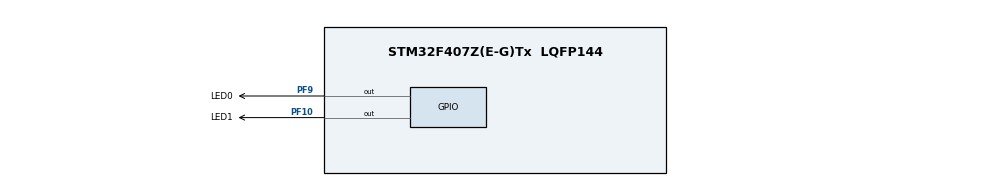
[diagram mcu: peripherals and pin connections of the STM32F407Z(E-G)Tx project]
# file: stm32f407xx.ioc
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Mcu.Family=STM32F4
Mcu.Name=STM32F407Z(E-G)Tx
Mcu.Package=LQFP144
NVIC.PriorityGroup=NVIC_PRIORITYGROUP_4
PA13.Mode=Serial_Wire
PA13.Signal=SYS_JTMS-SWDIO
PA14.Mode=Serial_Wire
PA14.Signal=SYS_JTCK-SWCLK
PC14-OSC32_IN.Mode=LSE-External-Oscillator
PC14-OSC32_IN.Signal=RCC_OSC32_IN
PC15-OSC32_OUT.Mode=LSE-External-Oscillator
PC15-OSC32_OUT.Signal=RCC_OSC32_OUT
PF10.GPIO_Label=LED1
PF10.GPIO_PuPd=GPIO_PULLUP
PF10.GPIO_Speed=GPIO_SPEED_FREQ_HIGH
PF10.PinState=GPIO_PIN_SET
PF10.Signal=GPIO_Output
PF9.GPIO_Label=LED0
PF9.GPIO_PuPd=GPIO_PULLUP
PF9.GPIO_Speed=GPIO_SPEED_FREQ_HIGH
PF9.PinState=GPIO_PIN_SET
PF9.Signal=GPIO_Output
PH0-OSC_IN.Mode=HSE-External-Oscillator
PH0-OSC_IN.Signal=RCC_OSC_IN
PH1-OSC_OUT.Mode=HSE-External-Oscillator
PH1-OSC_OUT.Signal=RCC_OSC_OUT
ProjectManager.HeapSize=0x200
ProjectManager.StackSize=0x400
ProjectManager.TargetToolchain=Makefile
RCC.48MHZClocksFreq_Value=84000000
RCC.AHBFreq_Value=168000000
RCC.APB1CLKDivider=RCC_HCLK_DIV4
RCC.APB1Freq_Value=42000000
RCC.APB1TimFreq_Value=84000000
RCC.APB2CLKDivider=RCC_HCLK_DIV2
RCC.APB2Freq_Value=84000000
RCC.APB2TimFreq_Value=168000000
RCC.CortexFreq_Value=168000000
RCC.HCLKFreq_Value=168000000
RCC.HSE_VALUE=8000000
RCC.HSI_VALUE=16000000
RCC.PLLM=8
RCC.PLLN=336
RCC.PLLSourceVirtual=RCC_PLLSOURCE_HSE
RCC.SYSCLKFreq_VALUE=168000000
RCC.SYSCLKSource=RCC_SYSCLKSOURCE_PLLCLK
RCC.VCOOutputFreq_Value=336000000
board=custom

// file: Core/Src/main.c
/* USER CODE BEGIN Header */
/**
  ******************************************************************************
  * @file           : main.c
  * @brief          : Main program body
  ******************************************************************************
  * @attention
  *
  * Copyright (c) 2023 STMicroelectronics.
  * All rights reserved.
  *
  * This software is licensed under terms that can be found in the LICENSE file
  * in the root directory of this software component.
  * If no LICENSE file comes with this software, it is provided AS-IS.
  *
  ******************************************************************************
  */
/* USER CODE END Header */

/* USER CODE BEGIN Includes */
#include "sys.h"
#include "led.h"
#include "usart.h"
#include "sram.h"
#include "lcd.h"
#include "delay.h"
#include "key.h"
#include "malloc.h"
#include "lvgl_demo.h"
#include "touch.h"
#include "ui.h"
/* USER CODE END Includes */

//void SystemClock_Config(void);

/* USER CODE BEGIN 0 */

uint8_t sys_stm32_clock_init(uint32_t plln, uint32_t pllm, uint32_t pllp, uint32_t pllq);
/* USER CODE END 0 */

//uint8_t str[1] __attribute__((section(".sram_data" )));

int main(void)
{

  /* MCU Configuration--------------------------------------------------------*/

  /* Reset of all peripherals, Initializes the Flash interface and the Systick. */
  HAL_Init();

  /* Configure the system clock */
  //SystemClock_Config();

  /* USER CODE BEGIN SysInit */
  sys_stm32_clock_init(336, 8, 2, 7); /* 设置时钟,168Mhz */
  delay_init(168);                    /* 初始化延时函数 */
  led_init();
  usart_init(115200);
  key_init();
  sram_init();
  tp_dev.init();
  my_mem_init(SRAMIN);                /* 初始化内部内存池 */
  my_mem_init(SRAMEX);                /* 初始化外部内存池 */

  /* USER CODE END SysInit */

  /* Initialize all configured peripherals */

  /* USER CODE BEGIN 2 */

  lvgl_demo();                        /* 运行FreeRTOS例程 */
  /* USER CODE END 2 */

  /* Infinite loop */
  while (1)
  {

  }
}

uint8_t sys_stm32_clock_init(uint32_t plln, uint32_t pllm, uint32_t pllp, uint32_t pllq)
{
  HAL_StatusTypeDef ret = HAL_OK;
  RCC_OscInitTypeDef rcc_osc_init = {0};
  RCC_ClkInitTypeDef rcc_clk_init = {0};

  __HAL_RCC_PWR_CLK_ENABLE();                                         /* 使能PWR时钟 */

  __HAL_PWR_VOLTAGESCALING_CONFIG(PWR_REGULATOR_VOLTAGE_SCALE1);      /* 设置调压器输出电压级别，以便在器件未以最大频率工作 */

  /* 使能HSE，并选择HSE作为PLL时钟源，配置PLL1，开启USB时钟 */
  rcc_osc_init.OscillatorType = RCC_OSCILLATORTYPE_HSE;        /* 时钟源为HSE */
  rcc_osc_init.HSEState = RCC_HSE_ON;                          /* 打开HSE */
  rcc_osc_init.PLL.PLLState = RCC_PLL_ON;                      /* 打开PLL */
  rcc_osc_init.PLL.PLLSource = RCC_PLLSOURCE_HSE;              /* PLL时钟源选择HSE */
  rcc_osc_init.PLL.PLLN = plln;
  rcc_osc_init.PLL.PLLM = pllm;
  rcc_osc_init.PLL.PLLP = pllp;
  rcc_osc_init.PLL.PLLQ = pllq;
  ret = HAL_RCC_OscConfig(&rcc_osc_init);                      /* 初始化RCC */
  if(ret != HAL_OK)
  {
    return 1;                                                /* 时钟初始化失败，可以在这里加入自己的处理 */
  }

  /* 选中PLL作为系统时钟源并且配置HCLK,PCLK1和PCLK2 */
  rcc_clk_init.ClockType = ( RCC_CLOCKTYPE_SYSCLK \
                                | RCC_CLOCKTYPE_HCLK \
                                | RCC_CLOCKTYPE_PCLK1 \
                                | RCC_CLOCKTYPE_PCLK2);

  rcc_clk_init.SYSCLKSource = RCC_SYSCLKSOURCE_PLLCLK;         /* 设置系统时钟时钟源为PLL */
  rcc_clk_init.AHBCLKDivider = RCC_SYSCLK_DIV1;                /* AHB分频系数为1 */
  rcc_clk_init.APB1CLKDivider = RCC_HCLK_DIV4;                 /* APB1分频系数为4 */
  rcc_clk_init.APB2CLKDivider = RCC_HCLK_DIV2;                 /* APB2分频系数为2 */
  ret = HAL_RCC_ClockConfig(&rcc_clk_init, FLASH_LATENCY_5);   /* 同时设置FLASH延时周期为5WS，也就是6个CPU周期 */
  if(ret != HAL_OK)
  {
    return 1;                                                /* 时钟初始化失败 */
  }

  /* STM32F405x/407x/415x/417x Z版本的器件支持预取功能 */
  if (HAL_GetREVID() == 0x1001)
  {
    __HAL_FLASH_PREFETCH_BUFFER_ENABLE();                    /* 使能flash预取 */
  }
  return 0;
}

void Error_Handler(void)
{
  __disable_irq();
  while (1)
  {
  }
}
